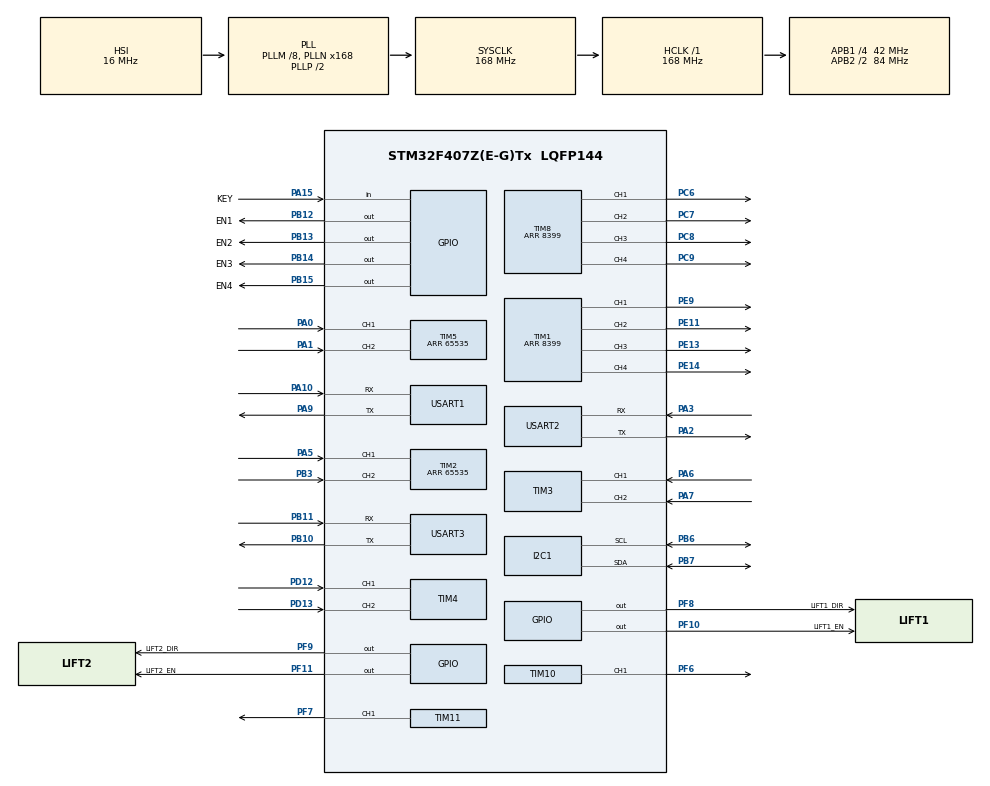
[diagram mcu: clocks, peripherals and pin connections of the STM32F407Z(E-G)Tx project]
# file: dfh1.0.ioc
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Dma.Request0=USART1_TX
Dma.USART1_TX.0.Direction=DMA_MEMORY_TO_PERIPH
Dma.USART1_TX.0.FIFOMode=DMA_FIFOMODE_DISABLE
Dma.USART1_TX.0.Instance=DMA2_Stream7
Dma.USART1_TX.0.MemDataAlignment=DMA_MDATAALIGN_BYTE
Dma.USART1_TX.0.MemInc=DMA_MINC_ENABLE
Dma.USART1_TX.0.Mode=DMA_NORMAL
Dma.USART1_TX.0.PeriphDataAlignment=DMA_PDATAALIGN_BYTE
Dma.USART1_TX.0.PeriphInc=DMA_PINC_DISABLE
Dma.USART1_TX.0.Priority=DMA_PRIORITY_LOW
I2C1.I2C_Mode=I2C_Fast
Mcu.Family=STM32F4
Mcu.Name=STM32F407Z(E-G)Tx
Mcu.Package=LQFP144
NVIC.DMA2_Stream7_IRQn=true\:0\:0\:false\:false\:true\:false\:true\:true
NVIC.PriorityGroup=NVIC_PRIORITYGROUP_4
NVIC.TIM1_TRG_COM_TIM11_IRQn=true\:5\:0\:true\:false\:true\:true\:true\:true
NVIC.TIM1_UP_TIM10_IRQn=true\:5\:0\:true\:false\:true\:true\:true\:true
NVIC.USART2_IRQn=true\:0\:0\:false\:false\:true\:true\:true\:true
NVIC.USART3_IRQn=true\:0\:0\:false\:false\:true\:true\:true\:true
PA0-WKUP.Signal=S_TIM5_CH1
PA1.Signal=S_TIM5_CH2
PA10.Mode=Asynchronous
PA10.Signal=USART1_RX
PA13.Mode=Serial_Wire
PA13.Signal=SYS_JTMS-SWDIO
PA14.Mode=Serial_Wire
PA14.Signal=SYS_JTCK-SWCLK
PA15.GPIO_Label=KEY
PA15.GPIO_PuPd=GPIO_PULLUP
PA15.Signal=GPIO_Input
PA2.Mode=Asynchronous
PA2.Signal=USART2_TX
PA3.Mode=Asynchronous
PA3.Signal=USART2_RX
PA5.GPIO_PuPd=GPIO_NOPULL
PA5.Signal=S_TIM2_CH1_ETR
PA6.Signal=S_TIM3_CH1
PA7.Signal=S_TIM3_CH2
PA9.Mode=Asynchronous
PA9.Signal=USART1_TX
PB10.Mode=Asynchronous
PB10.Signal=USART3_TX
PB11.Mode=Asynchronous
PB11.Signal=USART3_RX
PB12.GPIO_Label=EN1
PB12.Signal=GPIO_Output
PB13.GPIO_Label=EN2
PB13.Signal=GPIO_Output
PB14.GPIO_Label=EN3
PB14.Signal=GPIO_Output
PB15.GPIO_Label=EN4
PB15.Signal=GPIO_Output
PB3.GPIO_PuPd=GPIO_NOPULL
PB3.Signal=S_TIM2_CH2
PB6.Mode=I2C
PB6.Signal=I2C1_SCL
PB7.Mode=I2C
PB7.Signal=I2C1_SDA
PC6.Signal=S_TIM8_CH1
PC7.Signal=S_TIM8_CH2
PC8.Signal=S_TIM8_CH3
PC9.Signal=S_TIM8_CH4
PD12.Signal=S_TIM4_CH1
PD13.Signal=S_TIM4_CH2
PE11.Signal=S_TIM1_CH2
PE13.Signal=S_TIM1_CH3
PE14.Signal=S_TIM1_CH4
PE9.Signal=S_TIM1_CH1
PF10.GPIO_Label=LIFT1_EN
PF10.GPIO_Speed=GPIO_SPEED_FREQ_MEDIUM
PF10.Signal=GPIO_Output
PF11.GPIO_Label=LIFT2_EN
PF11.GPIO_Speed=GPIO_SPEED_FREQ_MEDIUM
PF11.Signal=GPIO_Output
PF6.Signal=S_TIM10_CH1
PF7.Signal=S_TIM11_CH1
PF8.GPIO_Label=LIFT1_DIR
PF8.GPIO_Speed=GPIO_SPEED_FREQ_MEDIUM
PF8.PinState=GPIO_PIN_RESET
PF8.Signal=GPIO_Output
PF9.GPIO_Label=LIFT2_DIR
PF9.GPIO_Speed=GPIO_SPEED_FREQ_MEDIUM
PF9.Signal=GPIO_Output
PH0-OSC_IN.Mode=HSE-External-Oscillator
PH0-OSC_IN.Signal=RCC_OSC_IN
PH1-OSC_OUT.Mode=HSE-External-Oscillator
PH1-OSC_OUT.Signal=RCC_OSC_OUT
ProjectManager.HeapSize=0x200
ProjectManager.StackSize=0x400
ProjectManager.TargetToolchain=MDK-ARM V5.32
RCC.48MHZClocksFreq_Value=84000000
RCC.AHBFreq_Value=168000000
RCC.APB1CLKDivider=RCC_HCLK_DIV4
RCC.APB1Freq_Value=42000000
RCC.APB1TimFreq_Value=84000000
RCC.APB2CLKDivider=RCC_HCLK_DIV2
RCC.APB2Freq_Value=84000000
RCC.APB2TimFreq_Value=168000000
RCC.CortexFreq_Value=168000000
RCC.HCLKFreq_Value=168000000
RCC.HSE_VALUE=25000000
RCC.HSI_VALUE=16000000
RCC.LSE_VALUE=32768
RCC.PLLM=8
RCC.PLLN=168
RCC.SYSCLKFreq_VALUE=168000000
RCC.SYSCLKSource=RCC_SYSCLKSOURCE_PLLCLK
RCC.VCOOutputFreq_Value=336000000
SH.S_TIM10_CH1.0=TIM10_CH1,PWM Generation1 CH1
SH.S_TIM11_CH1.0=TIM11_CH1,PWM Generation1 CH1
SH.S_TIM1_CH1.0=TIM1_CH1,PWM Generation1 CH1
SH.S_TIM1_CH2.0=TIM1_CH2,PWM Generation2 CH2
SH.S_TIM1_CH3.0=TIM1_CH3,PWM Generation3 CH3
SH.S_TIM1_CH4.0=TIM1_CH4,PWM Generation4 CH4
SH.S_TIM2_CH1_ETR.0=TIM2_CH1,Encoder_Interface
SH.S_TIM2_CH2.0=TIM2_CH2,Encoder_Interface
SH.S_TIM3_CH1.0=TIM3_CH1,Encoder_Interface
SH.S_TIM3_CH2.0=TIM3_CH2,Encoder_Interface
SH.S_TIM4_CH1.0=TIM4_CH1,Encoder_Interface
SH.S_TIM4_CH2.0=TIM4_CH2,Encoder_Interface
SH.S_TIM5_CH1.0=TIM5_CH1,Encoder_Interface
SH.S_TIM5_CH2.0=TIM5_CH2,Encoder_Interface
SH.S_TIM8_CH1.0=TIM8_CH1,PWM Generation1 CH1
SH.S_TIM8_CH2.0=TIM8_CH2,PWM Generation2 CH2
SH.S_TIM8_CH3.0=TIM8_CH3,PWM Generation3 CH3
SH.S_TIM8_CH4.0=TIM8_CH4,PWM Generation4 CH4
TIM1.Channel-PWM\ Generation1\ CH1=TIM_CHANNEL_1
TIM1.Channel-PWM\ Generation2\ CH2=TIM_CHANNEL_2
TIM1.Channel-PWM\ Generation3\ CH3=TIM_CHANNEL_3
TIM1.Channel-PWM\ Generation4\ CH4=TIM_CHANNEL_4
TIM1.Period=8399
TIM10.Channel=TIM_CHANNEL_1
TIM10.Period=999
TIM10.Prescaler=167
TIM10.Pulse=500
TIM11.Channel=TIM_CHANNEL_1
TIM11.Period=999
TIM11.Prescaler=167
TIM11.Pulse=500
TIM2.EncoderMode=TIM_ENCODERMODE_TI12
TIM2.IC1Filter=8
TIM2.IC2Filter=8
TIM2.Period=65535
TIM3.EncoderMode=TIM_ENCODERMODE_TI12
TIM3.IC1Filter=8
TIM3.IC2Filter=8
TIM4.EncoderMode=TIM_ENCODERMODE_TI12
TIM4.IC1Filter=8
TIM4.IC2Filter=8
TIM5.EncoderMode=TIM_ENCODERMODE_TI12
TIM5.IC1Filter=8
TIM5.IC2Filter=8
TIM5.Period=65535
TIM8.Channel-PWM\ Generation1\ CH1=TIM_CHANNEL_1
TIM8.Channel-PWM\ Generation2\ CH2=TIM_CHANNEL_2
TIM8.Channel-PWM\ Generation3\ CH3=TIM_CHANNEL_3
TIM8.Channel-PWM\ Generation4\ CH4=TIM_CHANNEL_4
TIM8.Period=8399
USART1.VirtualMode=VM_ASYNC
USART2.VirtualMode=VM_ASYNC
USART3.VirtualMode=VM_ASYNC
VP_TIM10_VS_ClockSourceINT.Mode=Enable_Timer
VP_TIM11_VS_ClockSourceINT.Mode=Enable_Timer
board=custom

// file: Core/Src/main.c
/* USER CODE BEGIN Header */
/**
  ******************************************************************************
  * @file           : main.c
  * @brief          : Main program body
  ******************************************************************************
  * @attention
  *
  * Copyright (c) 2025 STMicroelectronics.
  * All rights reserved.
  *
  * This software is licensed under terms that can be found in the LICENSE file
  * in the root directory of this software component.
  * If no LICENSE file comes with this software, it is provided AS-IS.
  *
  ******************************************************************************
  */
/* USER CODE END Header */
#include "main.h"
#include "dma.h"
#include "i2c.h"
#include "tim.h"
#include "usart.h"
#include "gpio.h"

/* USER CODE BEGIN Includes */
#include "robot_app.h"
/* USER CODE END Includes */

void SystemClock_Config(void);

int main(void)
{

  /* MCU Configuration--------------------------------------------------------*/

  /* Reset of all peripherals, Initializes the Flash interface and the Systick. */
  HAL_Init();

  /* Configure the system clock */
  SystemClock_Config();

  /* Initialize all configured peripherals */
  MX_GPIO_Init();
  MX_DMA_Init();
  MX_USART1_UART_Init();
  MX_TIM2_Init();
  MX_TIM3_Init();
  MX_I2C1_Init();
  MX_TIM1_Init();
  MX_TIM4_Init();
  MX_TIM5_Init();
  MX_USART2_UART_Init();
  MX_TIM8_Init();
  MX_TIM10_Init();
  MX_TIM11_Init();
  MX_USART3_UART_Init();
  /* USER CODE BEGIN 2 */
	RobotApp_Init();
  /* USER CODE END 2 */

  /* Infinite loop */
  while (1)
  {

    /* USER CODE BEGIN 3 */
		RobotApp_Loop();
  }
  /* USER CODE END 3 */
}

void SystemClock_Config(void)
{
  RCC_OscInitTypeDef RCC_OscInitStruct = {0};
  RCC_ClkInitTypeDef RCC_ClkInitStruct = {0};

  /** Configure the main internal regulator output voltage
  */
  __HAL_RCC_PWR_CLK_ENABLE();
  __HAL_PWR_VOLTAGESCALING_CONFIG(PWR_REGULATOR_VOLTAGE_SCALE1);

  /** Initializes the RCC Oscillators according to the specified parameters
  * in the RCC_OscInitTypeDef structure.
  */
  RCC_OscInitStruct.OscillatorType = RCC_OSCILLATORTYPE_HSI;
  RCC_OscInitStruct.HSIState = RCC_HSI_ON;
  RCC_OscInitStruct.HSICalibrationValue = RCC_HSICALIBRATION_DEFAULT;
  RCC_OscInitStruct.PLL.PLLState = RCC_PLL_ON;
  RCC_OscInitStruct.PLL.PLLSource = RCC_PLLSOURCE_HSI;
  RCC_OscInitStruct.PLL.PLLM = 8;
  RCC_OscInitStruct.PLL.PLLN = 168;
  RCC_OscInitStruct.PLL.PLLP = RCC_PLLP_DIV2;
  RCC_OscInitStruct.PLL.PLLQ = 4;
  if (HAL_RCC_OscConfig(&RCC_OscInitStruct) != HAL_OK)
  {
    Error_Handler();
  }

  /** Initializes the CPU, AHB and APB buses clocks
  */
  RCC_ClkInitStruct.ClockType = RCC_CLOCKTYPE_HCLK|RCC_CLOCKTYPE_SYSCLK
                              |RCC_CLOCKTYPE_PCLK1|RCC_CLOCKTYPE_PCLK2;
  RCC_ClkInitStruct.SYSCLKSource = RCC_SYSCLKSOURCE_PLLCLK;
  RCC_ClkInitStruct.AHBCLKDivider = RCC_SYSCLK_DIV1;
  RCC_ClkInitStruct.APB1CLKDivider = RCC_HCLK_DIV4;
  RCC_ClkInitStruct.APB2CLKDivider = RCC_HCLK_DIV2;

  if (HAL_RCC_ClockConfig(&RCC_ClkInitStruct, FLASH_LATENCY_5) != HAL_OK)
  {
    Error_Handler();
  }
}

/* USER CODE BEGIN 4 */
void HAL_UART_TxCpltCallback(UART_HandleTypeDef *huart)
{
    RobotApp_UartTxCpltCallback(huart);
}

void HAL_UART_RxCpltCallback(UART_HandleTypeDef *huart)
{
    RobotApp_UartRxCpltCallback(huart);
}

void HAL_UART_ErrorCallback(UART_HandleTypeDef *huart)
{
    RobotApp_UartErrorCallback(huart);
}

void HAL_TIM_PWM_PulseFinishedCallback(TIM_HandleTypeDef *htim)
{
    RobotApp_TimPwmPulseFinishedCallback(htim);
}

/* USER CODE END 4 */

void Error_Handler(void)
{
  __disable_irq();
  while (1)
  {
  }
}
